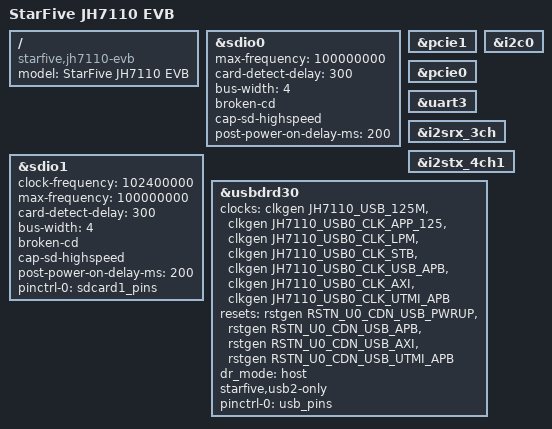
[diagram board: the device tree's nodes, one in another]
// SPDX-License-Identifier: GPL-2.0 OR MIT
/*
 * Copyright (C) 2022 StarFive Technology Co., Ltd.
 * Copyright (C) 2022 Hal Feng <hal.feng@starfivetech.com>
 */

/dts-v1/;
#include "jh7110-evb.dtsi"
#include "codecs/sf_wm8960.dtsi"

/ {
	model = "StarFive JH7110 EVB";
	compatible = "starfive,jh7110-evb", "starfive,jh7110";
};

/* default sd card */
&sdio0 {
	max-frequency = <100000000>;
	card-detect-delay = <300>;
	bus-width = <4>;
	broken-cd;
	cap-sd-highspeed;
	post-power-on-delay-ms = <200>;
	status = "okay";
};

&pcie1 {
	status = "okay";
};

&sdio1 {
	clock-frequency = <102400000>;
	max-frequency = <100000000>;
	card-detect-delay = <300>;
	bus-width = <4>;
	broken-cd;
	cap-sd-highspeed;
	post-power-on-delay-ms = <200>;
	pinctrl-names = "default";
	pinctrl-0 = <&sdcard1_pins>;
	status = "okay";
};

&pcie0 {
	status = "okay";
};

&uart3 {
	status = "okay";
};

&i2c0 {
	status = "okay";
};

&i2srx_3ch {
	status = "okay";
};

&i2stx_4ch1 {
	status = "okay";
};

&usbdrd30 {
	clocks = <&clkgen JH7110_USB_125M>,
		 <&clkgen JH7110_USB0_CLK_APP_125>,
		 <&clkgen JH7110_USB0_CLK_LPM>,
		 <&clkgen JH7110_USB0_CLK_STB>,
		 <&clkgen JH7110_USB0_CLK_USB_APB>,
		 <&clkgen JH7110_USB0_CLK_AXI>,
		 <&clkgen JH7110_USB0_CLK_UTMI_APB>;
	clock-names = "125m","app","lpm","stb","apb","axi","utmi";
	resets = <&rstgen RSTN_U0_CDN_USB_PWRUP>,
		 <&rstgen RSTN_U0_CDN_USB_APB>,
		 <&rstgen RSTN_U0_CDN_USB_AXI>,
		 <&rstgen RSTN_U0_CDN_USB_UTMI_APB>;
	reset-names = "pwrup","apb","axi","utmi";
	dr_mode = "host"; /*host or peripheral*/
	starfive,usb2-only;
	pinctrl-names = "default";
	pinctrl-0 = <&usb_pins>;
	status = "okay";
};
